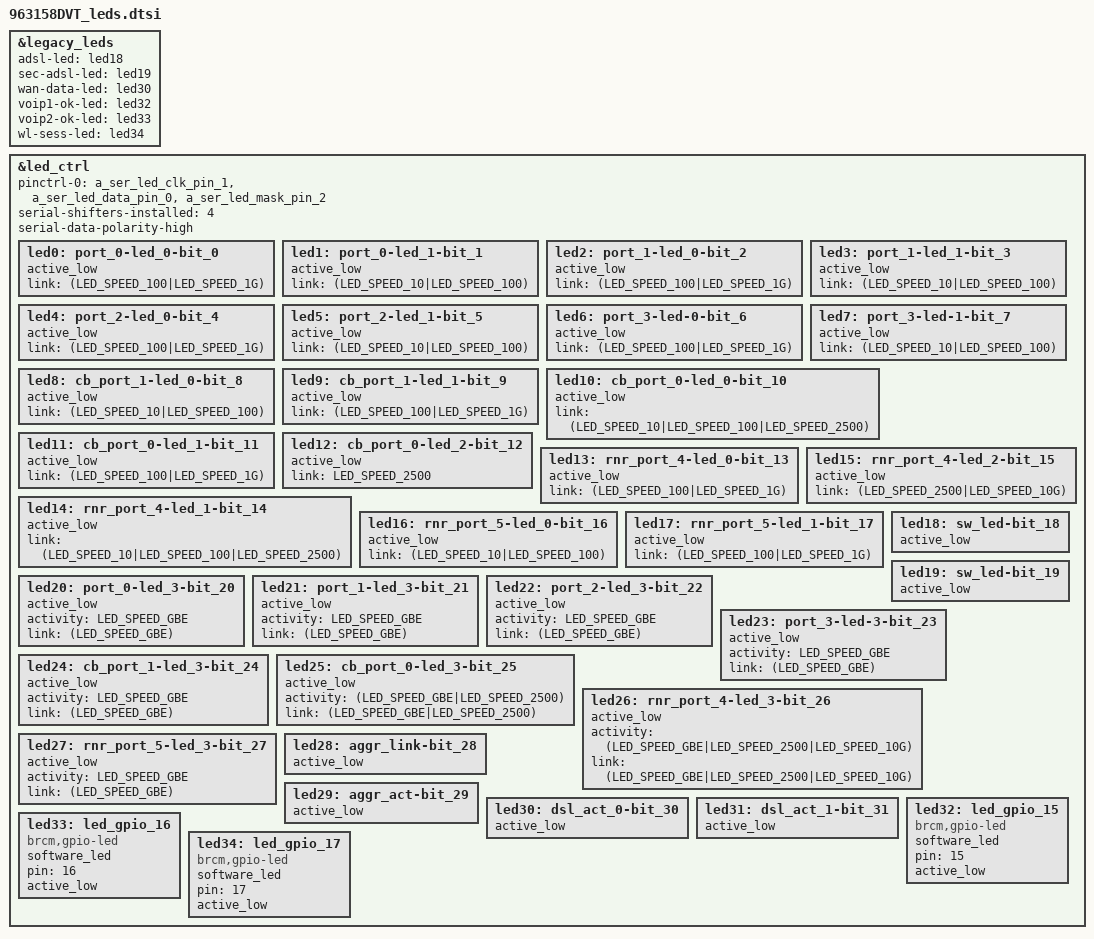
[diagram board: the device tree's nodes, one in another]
/* 963158DVT board led definition */

&legacy_leds {
	adsl-led = <&led18>;
	sec-adsl-led = <&led19>;
	wan-data-led = <&led30>;
	voip1-ok-led = <&led32>;
	voip2-ok-led = <&led33>;	
	wl-sess-led = <&led34>;
};

&led_ctrl {
	pinctrl-names = "default";
	pinctrl-0 = <&a_ser_led_clk_pin_1 &a_ser_led_data_pin_0 &a_ser_led_mask_pin_2>;
	serial-shifters-installed = <4>;
	serial-data-polarity-high;
	led0: port_0-led_0-bit_0 {
		active_low;
		link = <(LED_SPEED_100|LED_SPEED_1G)>;
		status = "okay";
	};
	led1: port_0-led_1-bit_1 {
		active_low;
		link = <(LED_SPEED_10|LED_SPEED_100)>;
		status = "okay";
	};
	led2: port_1-led_0-bit_2 {
		active_low;
		link = <(LED_SPEED_100|LED_SPEED_1G)>;
		status = "okay";
	};
	led3: port_1-led_1-bit_3 {
		active_low;
		link = <(LED_SPEED_10|LED_SPEED_100)>;
		status = "okay";
	};
	led4: port_2-led_0-bit_4 {
		active_low;
		link = <(LED_SPEED_100|LED_SPEED_1G)>;
		status = "okay";
	};
	led5: port_2-led_1-bit_5 {
		active_low;
		link = <(LED_SPEED_10|LED_SPEED_100)>;
		status = "okay";
	};
	led6: port_3-led-0-bit_6 {
		active_low;
		link = <(LED_SPEED_100|LED_SPEED_1G)>;
		status = "okay";
	};
	led7: port_3-led-1-bit_7 {
		active_low;
		link = <(LED_SPEED_10|LED_SPEED_100)>;
		status = "okay";
	};
	led8: cb_port_1-led_0-bit_8 {
		active_low;
		link = <(LED_SPEED_10|LED_SPEED_100)>;
		status = "okay";
	};
	led9: cb_port_1-led_1-bit_9 {
		active_low;
		link = <(LED_SPEED_100|LED_SPEED_1G)>;
		status = "okay";
	};
	led10: cb_port_0-led_0-bit_10 {
		active_low;
		link = <(LED_SPEED_10|LED_SPEED_100|LED_SPEED_2500)>;
		status = "okay";
	};
	led11: cb_port_0-led_1-bit_11 {
		active_low;
		link = <(LED_SPEED_100|LED_SPEED_1G)>;
		status = "okay";
	};
	led12: cb_port_0-led_2-bit_12 {
		active_low;
		link = <LED_SPEED_2500>;
		status = "okay";
	};
	led13: rnr_port_4-led_0-bit_13 {
		active_low;
		link = <(LED_SPEED_100|LED_SPEED_1G)>;
		status = "okay";
	};
	led14: rnr_port_4-led_1-bit_14 {
		active_low;
		link = <(LED_SPEED_10|LED_SPEED_100|LED_SPEED_2500)>;
		status = "okay";
	};
	led15: rnr_port_4-led_2-bit_15 {
		active_low;
		link = <(LED_SPEED_2500|LED_SPEED_10G)>;
		status = "okay";
	};
	led16: rnr_port_5-led_0-bit_16 {
		active_low;
		link = <(LED_SPEED_10|LED_SPEED_100)>;
		status = "okay";
	};
	led17: rnr_port_5-led_1-bit_17 {
		active_low;
		link = <(LED_SPEED_100|LED_SPEED_1G)>;
		status = "okay";
	};
	led18: sw_led-bit_18 {
		active_low;
		status = "okay";
	};
	led19: sw_led-bit_19 {
		active_low;
		status = "okay";
	};
	led20: port_0-led_3-bit_20 {
		active_low;
		activity = <LED_SPEED_GBE>;
		link = <(LED_SPEED_GBE)>;
		status = "okay";
	};
	led21: port_1-led_3-bit_21 {
		active_low;
		activity = <LED_SPEED_GBE>;
		link = <(LED_SPEED_GBE)>;
		status = "okay";
	};
	led22: port_2-led_3-bit_22 {
		active_low;
		activity = <LED_SPEED_GBE>;
		link = <(LED_SPEED_GBE)>;		
		status = "okay";
	};
	led23: port_3-led-3-bit_23 {
		active_low;
		activity = <LED_SPEED_GBE>;
		link = <(LED_SPEED_GBE)>;		
		status = "okay";
	};
	led24: cb_port_1-led_3-bit_24 {
		active_low;
		activity = <LED_SPEED_GBE>;
		link = <(LED_SPEED_GBE)>;
		status = "okay";
	};
	led25: cb_port_0-led_3-bit_25 {
		active_low;
		activity = <(LED_SPEED_GBE|LED_SPEED_2500)>;
		link = <(LED_SPEED_GBE|LED_SPEED_2500)>;
		status = "okay";
	};
	led26: rnr_port_4-led_3-bit_26 {
		active_low;
		activity = <(LED_SPEED_GBE|LED_SPEED_2500|LED_SPEED_10G)>;
		link = <(LED_SPEED_GBE|LED_SPEED_2500|LED_SPEED_10G)>;
		status = "okay";
	};
	led27: rnr_port_5-led_3-bit_27 {
		active_low;
		activity = <LED_SPEED_GBE>;
		link = <(LED_SPEED_GBE)>;
		status = "okay";
	};
	led28: aggr_link-bit_28 {
		active_low;
		status = "okay";
	};
	led29: aggr_act-bit_29 {
		active_low;
		status = "okay";
	};
	led30: dsl_act_0-bit_30 {
		active_low;
		status = "okay";
	};
	led31: dsl_act_1-bit_31 {
		active_low;
		status = "okay";
	};
	led32:led_gpio_15 {
		compatible = "brcm,gpio-led";
		software_led;
		pin = <15>;
		active_low;
	};
	led33:led_gpio_16 {
		compatible = "brcm,gpio-led";
		software_led;
		pin = <16>;
		active_low;
	};
	led34:led_gpio_17 {
		compatible = "brcm,gpio-led";
		software_led;
		pin = <17>;
		active_low;
	};
};
